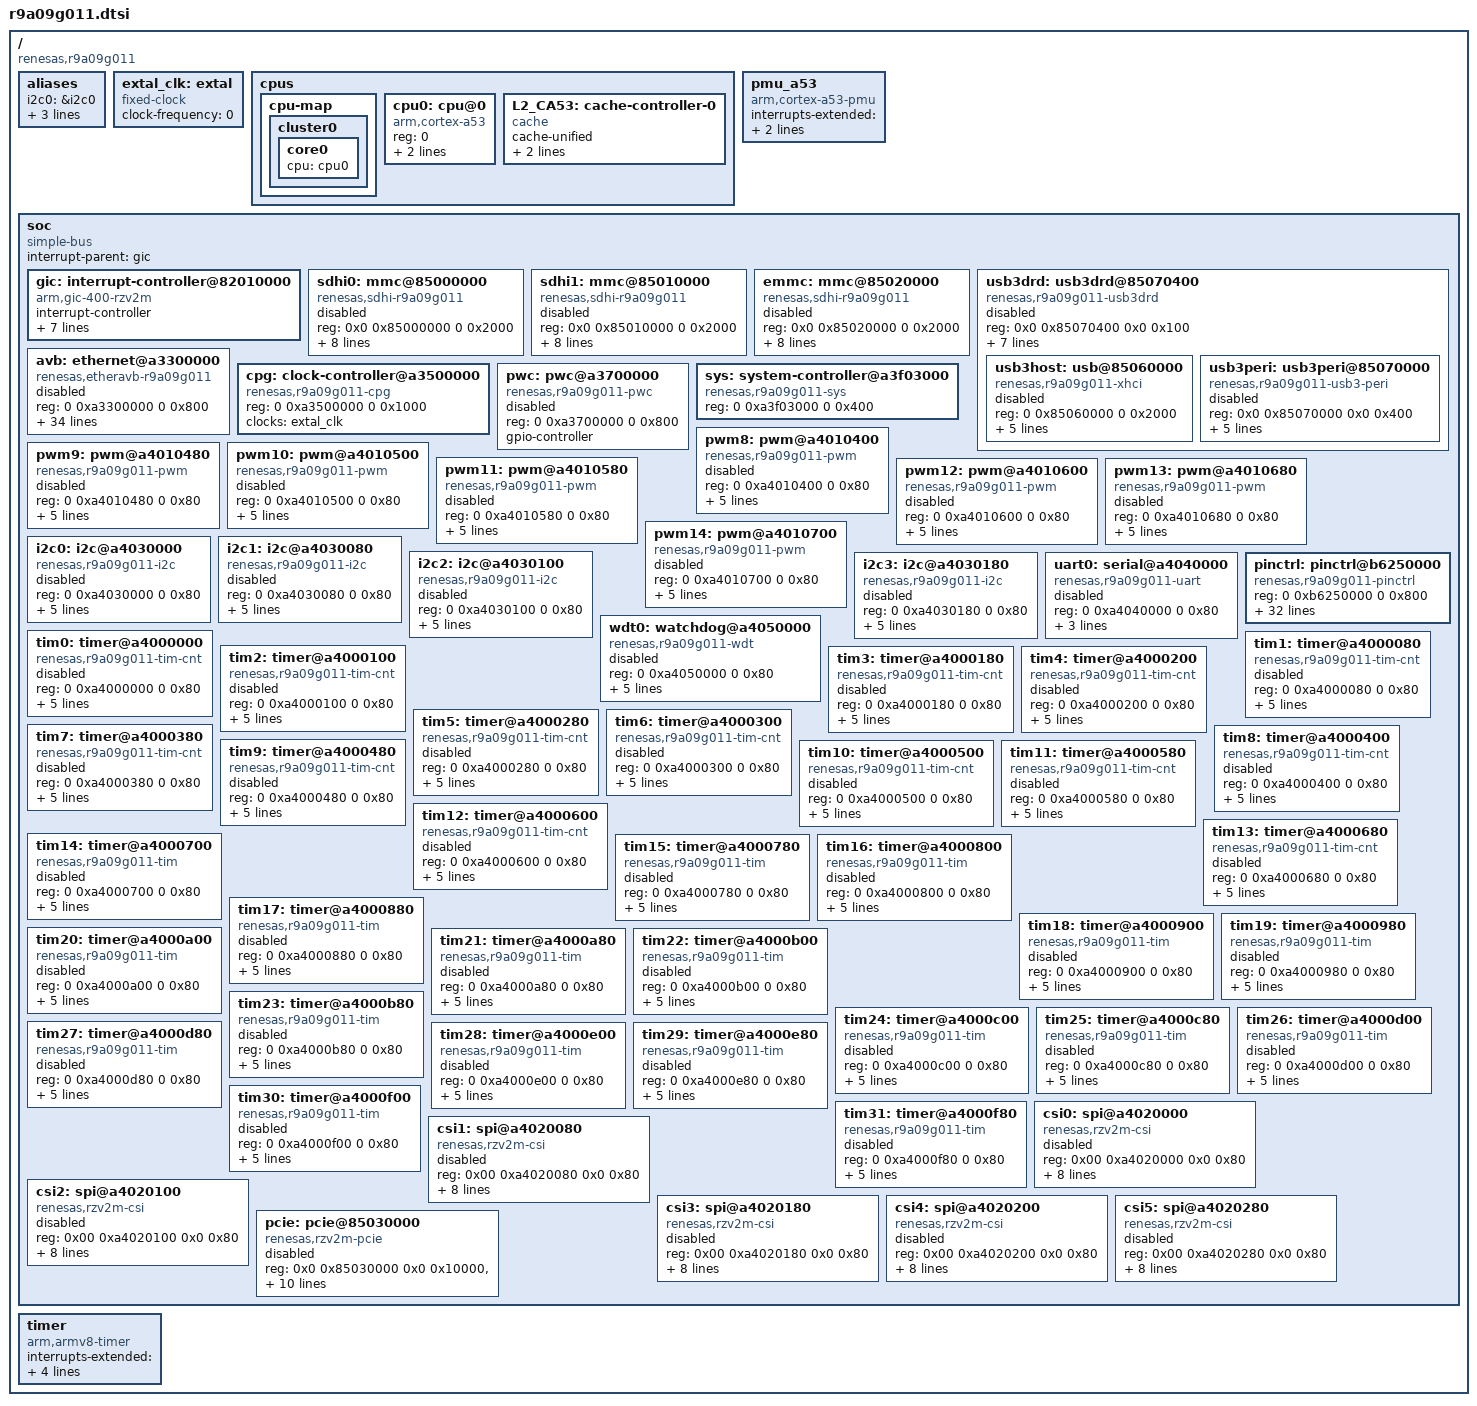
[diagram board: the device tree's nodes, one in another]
// SPDX-License-Identifier: (GPL-2.0-only OR BSD-2-Clause)
/*
 * Device Tree Source for the RZ/V2M SoC
 *
 * Copyright (C) 2022 Renesas Electronics Corp.
 */

#include <dt-bindings/interrupt-controller/arm-gic.h>
#include <dt-bindings/clock/r9a09g011-cpg.h>

/ {
	compatible = "renesas,r9a09g011";
	#address-cells = <2>;
	#size-cells = <2>;

	aliases {
		i2c0 = &i2c0;
		i2c1 = &i2c1;
		i2c2 = &i2c2;
		i2c3 = &i2c3;
	};

	/* clock can be either from exclk or crystal oscillator (XIN/XOUT) */
	extal_clk: extal {
		compatible = "fixed-clock";
		#clock-cells = <0>;
		/* This value must be overridden by the board */
		clock-frequency = <0>;
	};

	cpus {
		#address-cells = <1>;
		#size-cells = <0>;

		cpu-map {
			cluster0 {
				core0 {
					cpu = <&cpu0>;
				};
			};
		};

		cpu0: cpu@0 {
			compatible = "arm,cortex-a53";
			reg = <0>;
			device_type = "cpu";
			next-level-cache = <&L2_CA53>;
			clocks = <&cpg CPG_MOD R9A09G011_CA53_CLK>;
		};

		L2_CA53: cache-controller-0 {
			compatible = "cache";
			cache-unified;
			cache-level = <2>;
			cache-size = <0x80000>;
		};
	};


    	pmu_a53 { /* Support only for core0 not core1 */
		compatible = "arm,cortex-a53-pmu";
		interrupts-extended = <&gic GIC_SPI 6 IRQ_TYPE_LEVEL_HIGH>;
		interrupt-affinity = <&cpu0>;
    	};

	soc: soc {
		compatible = "simple-bus";
		interrupt-parent = <&gic>;
		#address-cells = <2>;
		#size-cells = <2>;
		ranges;

		gic: interrupt-controller@82010000 {
			compatible = "arm,gic-400-rzv2m";
			#interrupt-cells = <3>;
			#address-cells = <0>;
			interrupt-controller;
			reg = <0x0 0x82010000 0 0x1000>,
			      <0x0 0x82020000 0 0x20000>,
			      <0x0 0x82040000 0 0x20000>,
			      <0x0 0x82060000 0 0x20000>;
			interrupts = <GIC_PPI 9 (GIC_CPU_MASK_SIMPLE(1) | IRQ_TYPE_LEVEL_HIGH)>;
			clocks = <&cpg CPG_MOD R9A09G011_GIC_CLK>;
			clock-names = "clk";
		};

		sdhi0: mmc@85000000 {
			compatible = "renesas,sdhi-r9a09g011",
				     "renesas,rcar-gen3-sdhi";
			reg = <0x0 0x85000000 0 0x2000>;
			interrupts = <GIC_SPI 356 IRQ_TYPE_LEVEL_HIGH>,
				     <GIC_SPI 357 IRQ_TYPE_LEVEL_HIGH>;
			clocks = <&cpg CPG_MOD R9A09G011_SDI0_IMCLK>,
				 <&cpg CPG_MOD R9A09G011_SDI0_CLK_HS>,
				 <&cpg CPG_MOD R9A09G011_SDI0_IMCLK2>,
				 <&cpg CPG_MOD R9A09G011_SDI0_ACLK>;
			clock-names = "core", "clkh", "cd", "aclk";
			resets = <&cpg R9A09G011_SDI0_IXRST>;
			power-domains = <&cpg>;
			status = "disabled";
		};

		sdhi1: mmc@85010000  {
			compatible = "renesas,sdhi-r9a09g011",
				     "renesas,rcar-gen3-sdhi";
			reg = <0x0 0x85010000 0 0x2000>;
			interrupts = <GIC_SPI 358 IRQ_TYPE_LEVEL_HIGH>,
				     <GIC_SPI 359 IRQ_TYPE_LEVEL_HIGH>;
			clocks = <&cpg CPG_MOD R9A09G011_SDI1_IMCLK>,
				 <&cpg CPG_MOD R9A09G011_SDI1_CLK_HS>,
				 <&cpg CPG_MOD R9A09G011_SDI1_IMCLK2>,
				 <&cpg CPG_MOD R9A09G011_SDI1_ACLK>;
			clock-names = "core", "clkh", "cd", "aclk";
			resets = <&cpg R9A09G011_SDI1_IXRST>;
			power-domains = <&cpg>;
			status = "disabled";
		};

		emmc: mmc@85020000  {
			compatible = "renesas,sdhi-r9a09g011",
				     "renesas,rcar-gen3-sdhi";
			reg = <0x0 0x85020000 0 0x2000>;
			interrupts = <GIC_SPI 354 IRQ_TYPE_LEVEL_HIGH>,
				     <GIC_SPI 355 IRQ_TYPE_LEVEL_HIGH>;
			clocks = <&cpg CPG_MOD R9A09G011_EMM_IMCLK>,
				 <&cpg CPG_MOD R9A09G011_EMM_CLK_HS>,
				 <&cpg CPG_MOD R9A09G011_EMM_IMCLK2>,
				 <&cpg CPG_MOD R9A09G011_EMM_ACLK>;
			clock-names = "core", "clkh", "cd", "aclk";
			resets = <&cpg R9A09G011_EMM_IXRST>;
			power-domains = <&cpg>;
			status = "disabled";
		};

		usb3drd: usb3drd@85070400 {
			compatible = "renesas,r9a09g011-usb3drd",
				     "renesas,rzv2m-usb3drd";
			reg = <0x0 0x85070400 0x0 0x100>;
			interrupts = <GIC_SPI 242 IRQ_TYPE_LEVEL_HIGH>,
				      <GIC_SPI 243 IRQ_TYPE_LEVEL_HIGH>,
				      <GIC_SPI 244 IRQ_TYPE_LEVEL_HIGH>;
			interrupt-names = "drd", "bc", "gpi";
			clocks = <&cpg CPG_MOD R9A09G011_USB_ACLK_P>,
				 <&cpg CPG_MOD R9A09G011_USB_PCLK>;
			clock-names = "axi", "reg";
			resets = <&cpg R9A09G011_USB_DRD_RESET>;
			power-domains = <&cpg>;
			ranges;
			#address-cells = <2>;
			#size-cells = <2>;
			status = "disabled";

			usb3host: usb@85060000 {
				compatible = "renesas,r9a09g011-xhci",
					     "renesas,rzv2m-xhci";
				reg = <0 0x85060000 0 0x2000>;
				interrupts = <GIC_SPI 245 IRQ_TYPE_LEVEL_HIGH>;
				clocks = <&cpg CPG_MOD R9A09G011_USB_ACLK_H>,
					 <&cpg CPG_MOD R9A09G011_USB_PCLK>;
				clock-names = "axi", "reg";
				resets = <&cpg R9A09G011_USB_ARESETN_H>;
				power-domains = <&cpg>;
				status = "disabled";
			};

			usb3peri: usb3peri@85070000 {
				compatible = "renesas,r9a09g011-usb3-peri",
					     "renesas,rzv2m-usb3-peri";
				reg = <0x0 0x85070000 0x0 0x400>;
				interrupts = <GIC_SPI 246 IRQ_TYPE_LEVEL_HIGH>;
				clocks = <&cpg CPG_MOD R9A09G011_USB_ACLK_P>,
					 <&cpg CPG_MOD R9A09G011_USB_PCLK>;
				clock-names = "axi", "reg";
				resets = <&cpg R9A09G011_USB_ARESETN_P>;
				power-domains = <&cpg>;
				status = "disabled";
			};
		};

		avb: ethernet@a3300000 {
			compatible = "renesas,etheravb-r9a09g011","renesas,etheravb-rzv2m";
			reg = <0 0xa3300000 0 0x800>;
			interrupts = <GIC_SPI 251 IRQ_TYPE_LEVEL_HIGH>, /* ch0: Rx0 BE */
				     <GIC_SPI 252 IRQ_TYPE_LEVEL_HIGH>, /* ch1: Rx1 NC */
				     <GIC_SPI 253 IRQ_TYPE_LEVEL_HIGH>,
				     <GIC_SPI 254 IRQ_TYPE_LEVEL_HIGH>,
				     <GIC_SPI 255 IRQ_TYPE_LEVEL_HIGH>,
				     <GIC_SPI 256 IRQ_TYPE_LEVEL_HIGH>,
				     <GIC_SPI 257 IRQ_TYPE_LEVEL_HIGH>,
				     <GIC_SPI 258 IRQ_TYPE_LEVEL_HIGH>,
				     <GIC_SPI 259 IRQ_TYPE_LEVEL_HIGH>,
				     <GIC_SPI 260 IRQ_TYPE_LEVEL_HIGH>,
				     <GIC_SPI 261 IRQ_TYPE_LEVEL_HIGH>,
				     <GIC_SPI 262 IRQ_TYPE_LEVEL_HIGH>,
				     <GIC_SPI 263 IRQ_TYPE_LEVEL_HIGH>,
				     <GIC_SPI 264 IRQ_TYPE_LEVEL_HIGH>,
				     <GIC_SPI 265 IRQ_TYPE_LEVEL_HIGH>,
				     <GIC_SPI 266 IRQ_TYPE_LEVEL_HIGH>,
				     <GIC_SPI 267 IRQ_TYPE_LEVEL_HIGH>,
				     <GIC_SPI 268 IRQ_TYPE_LEVEL_HIGH>,
				     <GIC_SPI 269 IRQ_TYPE_LEVEL_HIGH>, /* ch18: Tx0 BE */
				     <GIC_SPI 270 IRQ_TYPE_LEVEL_HIGH>, /* ch19: Tx1 NC */
				     <GIC_SPI 271 IRQ_TYPE_LEVEL_HIGH>,
				     <GIC_SPI 272 IRQ_TYPE_LEVEL_HIGH>,
				     <GIC_SPI 273 IRQ_TYPE_LEVEL_HIGH>, /* DiA */
				     <GIC_SPI 274 IRQ_TYPE_LEVEL_HIGH>, /* DiB */
				     <GIC_SPI 275 IRQ_TYPE_LEVEL_HIGH>, /* Line1_A */
				     <GIC_SPI 276 IRQ_TYPE_LEVEL_HIGH>, /* Line1_B */
				     <GIC_SPI 277 IRQ_TYPE_LEVEL_HIGH>, /* Line2_A */
				     <GIC_SPI 278 IRQ_TYPE_LEVEL_HIGH>, /* Line2_B */
				     <GIC_SPI 279 IRQ_TYPE_LEVEL_HIGH>; /* Line3 MAC */
			interrupt-names = "ch0", "ch1", "ch2", "ch3",
					  "ch4", "ch5", "ch6", "ch7",
					  "ch8", "ch9", "ch10", "ch11",
					  "ch12", "ch13", "ch14", "ch15",
					  "ch16", "ch17", "ch18", "ch19",
					  "ch20", "ch21", "dia", "dib",
					  "err_a", "err_b", "mgmt_a", "mgmt_b",
					  "line3";
			clocks = <&cpg CPG_MOD R9A09G011_ETH0_CLK_AXI>,
				 <&cpg CPG_MOD R9A09G011_ETH0_CLK_CHI>,
				 <&cpg CPG_MOD R9A09G011_ETH0_GPTP_EXT>;
			clock-names = "axi", "chi", "gptp";
			resets = <&cpg R9A09G011_ETH0_RST_HW_N>;
			power-domains = <&cpg>;
			#address-cells = <1>;
			#size-cells = <0>;
			status = "disabled";
		};

		cpg: clock-controller@a3500000 {
			compatible = "renesas,r9a09g011-cpg";
			reg = <0 0xa3500000 0 0x1000>;
			clocks = <&extal_clk>;
			clock-names = "extal";
			#clock-cells = <2>;
			#reset-cells = <1>;
			#power-domain-cells = <0>;
		};

		pwc: pwc@a3700000 {
			compatible = "renesas,r9a09g011-pwc", "renesas,rzv2m-pwc";
			reg = <0 0xa3700000 0 0x800>;
			gpio-controller;
			#gpio-cells = <2>;
			status = "disabled";
		};

		sys: system-controller@a3f03000 {
			compatible = "renesas,r9a09g011-sys";
			reg = <0 0xa3f03000 0 0x400>;
		};

		pwm8: pwm@a4010400 {
			compatible = "renesas,r9a09g011-pwm",
				     "renesas,rzv2m-pwm";
			reg = <0 0xa4010400 0 0x80>;
			interrupts = <GIC_SPI 376 IRQ_TYPE_LEVEL_HIGH>;
			clocks = <&cpg CPG_MOD R9A09G011_CPERI_GRPF_PCLK>,
				 <&cpg CPG_MOD R9A09G011_PWM8_CLK>;
			clock-names = "apb", "pwm";
			resets = <&cpg R9A09G011_PWM_GPF_PRESETN>;
			power-domains = <&cpg>;
			#pwm-cells = <2>;
			status = "disabled";
		};

		pwm9: pwm@a4010480 {
			compatible = "renesas,r9a09g011-pwm",
				     "renesas,rzv2m-pwm";
			reg = <0 0xa4010480 0 0x80>;
			interrupts = <GIC_SPI 377 IRQ_TYPE_LEVEL_HIGH>;
			clocks = <&cpg CPG_MOD R9A09G011_CPERI_GRPF_PCLK>,
				 <&cpg CPG_MOD R9A09G011_PWM9_CLK>;
			clock-names = "apb", "pwm";
			resets = <&cpg R9A09G011_PWM_GPF_PRESETN>;
			power-domains = <&cpg>;
			#pwm-cells = <2>;
			status = "disabled";
		};

		pwm10: pwm@a4010500 {
			compatible = "renesas,r9a09g011-pwm",
				     "renesas,rzv2m-pwm";
			reg = <0 0xa4010500 0 0x80>;
			interrupts = <GIC_SPI 378 IRQ_TYPE_LEVEL_HIGH>;
			clocks = <&cpg CPG_MOD R9A09G011_CPERI_GRPF_PCLK>,
				 <&cpg CPG_MOD R9A09G011_PWM10_CLK>;
			clock-names = "apb", "pwm";
			resets = <&cpg R9A09G011_PWM_GPF_PRESETN>;
			power-domains = <&cpg>;
			#pwm-cells = <2>;
			status = "disabled";
		};

		pwm11: pwm@a4010580 {
			compatible = "renesas,r9a09g011-pwm",
				     "renesas,rzv2m-pwm";
			reg = <0 0xa4010580 0 0x80>;
			interrupts = <GIC_SPI 379 IRQ_TYPE_LEVEL_HIGH>;
			clocks = <&cpg CPG_MOD R9A09G011_CPERI_GRPF_PCLK>,
				 <&cpg CPG_MOD R9A09G011_PWM11_CLK>;
			clock-names = "apb", "pwm";
			resets = <&cpg R9A09G011_PWM_GPF_PRESETN>;
			power-domains = <&cpg>;
			#pwm-cells = <2>;
			status = "disabled";
		};

		pwm12: pwm@a4010600 {
			compatible = "renesas,r9a09g011-pwm",
				     "renesas,rzv2m-pwm";
			reg = <0 0xa4010600 0 0x80>;
			interrupts = <GIC_SPI 380 IRQ_TYPE_LEVEL_HIGH>;
			clocks = <&cpg CPG_MOD R9A09G011_CPERI_GRPF_PCLK>,
				 <&cpg CPG_MOD R9A09G011_PWM12_CLK>;
			clock-names = "apb", "pwm";
			resets = <&cpg R9A09G011_PWM_GPF_PRESETN>;
			power-domains = <&cpg>;
			#pwm-cells = <2>;
			status = "disabled";
		};

		pwm13: pwm@a4010680 {
			compatible = "renesas,r9a09g011-pwm",
				     "renesas,rzv2m-pwm";
			reg = <0 0xa4010680 0 0x80>;
			interrupts = <GIC_SPI 381 IRQ_TYPE_LEVEL_HIGH>;
			clocks = <&cpg CPG_MOD R9A09G011_CPERI_GRPF_PCLK>,
				 <&cpg CPG_MOD R9A09G011_PWM13_CLK>;
			clock-names = "apb", "pwm";
			resets = <&cpg R9A09G011_PWM_GPF_PRESETN>;
			power-domains = <&cpg>;
			#pwm-cells = <2>;
			status = "disabled";
		};

		pwm14: pwm@a4010700 {
			compatible = "renesas,r9a09g011-pwm",
				     "renesas,rzv2m-pwm";
			reg = <0 0xa4010700 0 0x80>;
			interrupts = <GIC_SPI 382 IRQ_TYPE_LEVEL_HIGH>;
			clocks = <&cpg CPG_MOD R9A09G011_CPERI_GRPF_PCLK>,
				 <&cpg CPG_MOD R9A09G011_PWM14_CLK>;
			clock-names = "apb", "pwm";
			resets = <&cpg R9A09G011_PWM_GPF_PRESETN>;
			power-domains = <&cpg>;
			#pwm-cells = <2>;
			status = "disabled";
		};

		i2c0: i2c@a4030000 {
			#address-cells = <1>;
			#size-cells = <0>;
			compatible = "renesas,r9a09g011-i2c", "renesas,rzv2m-i2c";
			reg = <0 0xa4030000 0 0x80>;
			interrupts = <GIC_SPI 232 IRQ_TYPE_EDGE_RISING>,
				     <GIC_SPI 236 IRQ_TYPE_EDGE_RISING>;
			interrupt-names = "tia", "tis";
			clocks = <&cpg CPG_MOD R9A09G011_IIC_PCLK0>;
			resets = <&cpg R9A09G011_IIC_GPA_PRESETN>;
			power-domains = <&cpg>;
			status = "disabled";
		};

                i2c1: i2c@a4030080 {
                        #address-cells = <1>;
                        #size-cells = <0>;
                        compatible = "renesas,r9a09g011-i2c", "renesas,rzv2m-i2c";
                        reg = <0 0xa4030080 0 0x80>;
                        interrupts = <GIC_SPI 233 IRQ_TYPE_EDGE_RISING>,
                                     <GIC_SPI 237 IRQ_TYPE_EDGE_RISING>;
                        interrupt-names = "tia", "tis";
                        clocks = <&cpg CPG_MOD R9A09G011_IIC_PCLK0>;
                        resets = <&cpg R9A09G011_IIC_GPA_PRESETN>;
                        power-domains = <&cpg>;
                        status = "disabled";
                };

		i2c2: i2c@a4030100 {
			#address-cells = <1>;
			#size-cells = <0>;
			compatible = "renesas,r9a09g011-i2c", "renesas,rzv2m-i2c";
			reg = <0 0xa4030100 0 0x80>;
			interrupts = <GIC_SPI 234 IRQ_TYPE_EDGE_RISING>,
				     <GIC_SPI 238 IRQ_TYPE_EDGE_RISING>;
			interrupt-names = "tia", "tis";
			clocks = <&cpg CPG_MOD R9A09G011_IIC_PCLK1>;
			resets = <&cpg R9A09G011_IIC_GPB_PRESETN>;
			power-domains = <&cpg>;
			status = "disabled";
		};

                i2c3: i2c@a4030180 {
                        #address-cells = <1>;
                        #size-cells = <0>;
                        compatible = "renesas,r9a09g011-i2c", "renesas,rzv2m-i2c";
                        reg = <0 0xa4030180 0 0x80>;
                        interrupts = <GIC_SPI 235 IRQ_TYPE_EDGE_RISING>,
                                     <GIC_SPI 239 IRQ_TYPE_EDGE_RISING>;
                        interrupt-names = "tia", "tis";
                        clocks = <&cpg CPG_MOD R9A09G011_IIC_PCLK1>;
                        resets = <&cpg R9A09G011_IIC_GPB_PRESETN>;
                        power-domains = <&cpg>;
                        status = "disabled";
                };

		uart0: serial@a4040000 {
			compatible = "renesas,r9a09g011-uart", "renesas,em-uart";
			reg = <0 0xa4040000 0 0x80>;
			interrupts = <GIC_SPI 240 IRQ_TYPE_LEVEL_HIGH>;
			clocks = <&cpg CPG_MOD R9A09G011_URT0_CLK>,
				 <&cpg CPG_MOD R9A09G011_URT_PCLK>;
			clock-names = "sclk", "pclk";
			status = "disabled";
		};

		wdt0: watchdog@a4050000 {
			compatible = "renesas,r9a09g011-wdt",
				     "renesas,rzv2m-wdt";
			reg = <0 0xa4050000 0 0x80>;
			clocks = <&cpg CPG_MOD R9A09G011_WDT0_PCLK>,
				 <&cpg CPG_MOD R9A09G011_WDT0_CLK>;
			clock-names = "pclk", "oscclk";
			interrupts = <GIC_SPI 43 IRQ_TYPE_LEVEL_HIGH>;
			resets = <&cpg R9A09G011_WDT0_PRESETN>;
			power-domains = <&cpg>;
			status = "disabled";
		};

		pinctrl: pinctrl@b6250000 {
			compatible = "renesas,r9a09g011-pinctrl";
			reg = <0 0xb6250000 0 0x800>;
			gpio-controller;
			#gpio-cells = <2>;
			gpio-ranges = <&pinctrl 0 0 352>;
			interrupt-controller;
			#interrupt-cells = <2>;
			interrupts = <GIC_SPI 72 IRQ_TYPE_LEVEL_HIGH>,
				     <GIC_SPI 73 IRQ_TYPE_LEVEL_HIGH>,
				     <GIC_SPI 74 IRQ_TYPE_LEVEL_HIGH>,
				     <GIC_SPI 75 IRQ_TYPE_LEVEL_HIGH>,
				     <GIC_SPI 84 IRQ_TYPE_LEVEL_HIGH>,
				     <GIC_SPI 85 IRQ_TYPE_LEVEL_HIGH>,
				     <GIC_SPI 86 IRQ_TYPE_LEVEL_HIGH>,
				     <GIC_SPI 87 IRQ_TYPE_LEVEL_HIGH>,
				     <GIC_SPI 88 IRQ_TYPE_LEVEL_HIGH>,
				     <GIC_SPI 89 IRQ_TYPE_LEVEL_HIGH>,
				     <GIC_SPI 90 IRQ_TYPE_LEVEL_HIGH>,
				     <GIC_SPI 92 IRQ_TYPE_LEVEL_HIGH>,
				     <GIC_SPI 93 IRQ_TYPE_LEVEL_HIGH>,
				     <GIC_SPI 94 IRQ_TYPE_LEVEL_HIGH>,
				     <GIC_SPI 95 IRQ_TYPE_LEVEL_HIGH>,
				     <GIC_SPI 96 IRQ_TYPE_LEVEL_HIGH>,
				     <GIC_SPI 97 IRQ_TYPE_LEVEL_HIGH>,
				     <GIC_SPI 98 IRQ_TYPE_LEVEL_HIGH>,
				     <GIC_SPI 99 IRQ_TYPE_LEVEL_HIGH>,
				     <GIC_SPI 100 IRQ_TYPE_LEVEL_HIGH>,
				     <GIC_SPI 101 IRQ_TYPE_LEVEL_HIGH>,
				     <GIC_SPI 102 IRQ_TYPE_LEVEL_HIGH>,
				     <GIC_SPI 103 IRQ_TYPE_LEVEL_HIGH>,
				     <GIC_SPI 104 IRQ_TYPE_LEVEL_HIGH>,
				     <GIC_SPI 105 IRQ_TYPE_LEVEL_HIGH>,
				     <GIC_SPI 106 IRQ_TYPE_LEVEL_HIGH>;
			interrupt-names = "inexint4", "inexint5",
					  "inexint6", "inexint7",
					  "inexint16", "inexint17",
					  "inexint18", "inexint19",
					  "inexint20", "inexint21",
					  "inexint22", "inexint24",
					  "inexint25", "inexint26",
					  "inexint27", "inexint28",
					  "inexint29", "inexint30",
					  "inexint31", "inexint32",
					  "inexint33", "inexint34",
					  "inexint35", "inexint36",
					  "inexint37", "inexint38";
			clocks = <&cpg CPG_MOD R9A09G011_PFC_PCLK>;
			power-domains = <&cpg>;
			resets = <&cpg R9A09G011_PFC_PRESETN>;
		};

		tim0: timer@a4000000 {
			compatible = "renesas,r9a09g011-tim-cnt",
				     "renesas,rzv2m-tim-cnt";
			reg = <0 0xa4000000 0 0x80>;
			interrupts = <GIC_SPI 107 IRQ_TYPE_LEVEL_HIGH>;
			clocks = <&cpg CPG_MOD R9A09G011_CPERI_GRPA_PCLK>,
				 <&cpg CPG_MOD R9A09G011_TIM0_CLK>;
			clock-names = "apb", "timclk";
			resets = <&cpg R9A09G011_TIM_GPA_PRESETN>;
			power-domains = <&cpg>;
			status = "disabled";
		};

		tim1: timer@a4000080 {
			compatible = "renesas,r9a09g011-tim-cnt",
				     "renesas,rzv2m-tim-cnt";
			reg = <0 0xa4000080 0 0x80>;
			interrupts = <GIC_SPI 108 IRQ_TYPE_LEVEL_HIGH>;
			clocks = <&cpg CPG_MOD R9A09G011_CPERI_GRPA_PCLK>,
				 <&cpg CPG_MOD R9A09G011_TIM1_CLK>;
			clock-names = "apb", "timclk";
			resets = <&cpg R9A09G011_TIM_GPA_PRESETN>;
			power-domains = <&cpg>;
			status = "disabled";
		};

		tim2: timer@a4000100 {
			compatible = "renesas,r9a09g011-tim-cnt",
				     "renesas,rzv2m-tim-cnt";
			reg = <0 0xa4000100 0 0x80>;
			interrupts = <GIC_SPI 109 IRQ_TYPE_LEVEL_HIGH>;
			clocks = <&cpg CPG_MOD R9A09G011_CPERI_GRPA_PCLK>,
				 <&cpg CPG_MOD R9A09G011_TIM2_CLK>;
			clock-names = "apb", "timclk";
			resets = <&cpg R9A09G011_TIM_GPA_PRESETN>;
			power-domains = <&cpg>;
			status = "disabled";
		};

		tim3: timer@a4000180 {
			compatible = "renesas,r9a09g011-tim-cnt",
				     "renesas,rzv2m-tim-cnt";
			reg = <0 0xa4000180 0 0x80>;
			interrupts = <GIC_SPI 110 IRQ_TYPE_LEVEL_HIGH>;
			clocks = <&cpg CPG_MOD R9A09G011_CPERI_GRPA_PCLK>,
				 <&cpg CPG_MOD R9A09G011_TIM3_CLK>;
			clock-names = "apb", "timclk";
			resets = <&cpg R9A09G011_TIM_GPA_PRESETN>;
			power-domains = <&cpg>;
			status = "disabled";
		};

		tim4: timer@a4000200 {
			compatible = "renesas,r9a09g011-tim-cnt",
				     "renesas,rzv2m-tim-cnt";
			reg = <0 0xa4000200 0 0x80>;
			interrupts = <GIC_SPI 111 IRQ_TYPE_LEVEL_HIGH>;
			clocks = <&cpg CPG_MOD R9A09G011_CPERI_GRPA_PCLK>,
				 <&cpg CPG_MOD R9A09G011_TIM4_CLK>;
			clock-names = "apb", "timclk";
			resets = <&cpg R9A09G011_TIM_GPA_PRESETN>;
			power-domains = <&cpg>;
			status = "disabled";
		};

		tim5: timer@a4000280 {
			compatible = "renesas,r9a09g011-tim-cnt",
				     "renesas,rzv2m-tim-cnt";
			reg = <0 0xa4000280 0 0x80>;
			interrupts = <GIC_SPI 112 IRQ_TYPE_LEVEL_HIGH>;
			clocks = <&cpg CPG_MOD R9A09G011_CPERI_GRPA_PCLK>,
				 <&cpg CPG_MOD R9A09G011_TIM5_CLK>;
			clock-names = "apb", "timclk";
			resets = <&cpg R9A09G011_TIM_GPA_PRESETN>;
			power-domains = <&cpg>;
			status = "disabled";
		};

		tim6: timer@a4000300 {
			compatible = "renesas,r9a09g011-tim-cnt",
				     "renesas,rzv2m-tim-cnt";
			reg = <0 0xa4000300 0 0x80>;
			interrupts = <GIC_SPI 113 IRQ_TYPE_LEVEL_HIGH>;
			clocks = <&cpg CPG_MOD R9A09G011_CPERI_GRPA_PCLK>,
				 <&cpg CPG_MOD R9A09G011_TIM6_CLK>;
			clock-names = "apb", "timclk";
			resets = <&cpg R9A09G011_TIM_GPA_PRESETN>;
			power-domains = <&cpg>;
			status = "disabled";
		};

		tim7: timer@a4000380 {
			compatible = "renesas,r9a09g011-tim-cnt",
				     "renesas,rzv2m-tim-cnt";
			reg = <0 0xa4000380 0 0x80>;
			interrupts = <GIC_SPI 114 IRQ_TYPE_LEVEL_HIGH>;
			clocks = <&cpg CPG_MOD R9A09G011_CPERI_GRPA_PCLK>,
				 <&cpg CPG_MOD R9A09G011_TIM15_CLK>;
			clock-names = "apb", "timclk";
			resets = <&cpg R9A09G011_TIM_GPA_PRESETN>;
			power-domains = <&cpg>;
			status = "disabled";
		};

		tim8: timer@a4000400 {
			compatible = "renesas,r9a09g011-tim-cnt",
				     "renesas,rzv2m-tim-cnt";
			reg = <0 0xa4000400 0 0x80>;
			interrupts = <GIC_SPI 115 IRQ_TYPE_LEVEL_HIGH>;
			clocks = <&cpg CPG_MOD R9A09G011_CPERI_GRPB_PCLK>,
				 <&cpg CPG_MOD R9A09G011_TIM8_CLK>;
			clock-names = "apb", "timclk";
			resets = <&cpg R9A09G011_TIM_GPB_PRESETN>;
			power-domains = <&cpg>;
			status = "disabled";
		};

		tim9: timer@a4000480 {
			compatible = "renesas,r9a09g011-tim-cnt",
				     "renesas,rzv2m-tim-cnt";
			reg = <0 0xa4000480 0 0x80>;
			interrupts = <GIC_SPI 116 IRQ_TYPE_LEVEL_HIGH>;
			clocks = <&cpg CPG_MOD R9A09G011_CPERI_GRPB_PCLK>,
				 <&cpg CPG_MOD R9A09G011_TIM9_CLK>;
			clock-names = "apb", "timclk";
			resets = <&cpg R9A09G011_TIM_GPB_PRESETN>;
			power-domains = <&cpg>;
			status = "disabled";
		};

		tim10: timer@a4000500 {
			compatible = "renesas,r9a09g011-tim-cnt",
				     "renesas,rzv2m-tim-cnt";
			reg = <0 0xa4000500 0 0x80>;
			interrupts = <GIC_SPI 117 IRQ_TYPE_LEVEL_HIGH>;
			clocks = <&cpg CPG_MOD R9A09G011_CPERI_GRPB_PCLK>,
				 <&cpg CPG_MOD R9A09G011_TIM10_CLK>;
			clock-names = "apb", "timclk";
			resets = <&cpg R9A09G011_TIM_GPB_PRESETN>;
			power-domains = <&cpg>;
			status = "disabled";
		};

		tim11: timer@a4000580 {
			compatible = "renesas,r9a09g011-tim-cnt",
				     "renesas,rzv2m-tim-cnt";
			reg = <0 0xa4000580 0 0x80>;
			interrupts = <GIC_SPI 118 IRQ_TYPE_LEVEL_HIGH>;
			clocks = <&cpg CPG_MOD R9A09G011_CPERI_GRPB_PCLK>,
				 <&cpg CPG_MOD R9A09G011_TIM11_CLK>;
			clock-names = "apb", "timclk";
			resets = <&cpg R9A09G011_TIM_GPB_PRESETN>;
			power-domains = <&cpg>;
			status = "disabled";
		};

		tim12: timer@a4000600 {
			compatible = "renesas,r9a09g011-tim-cnt",
				     "renesas,rzv2m-tim-cnt";
			reg = <0 0xa4000600 0 0x80>;
			interrupts = <GIC_SPI 119 IRQ_TYPE_LEVEL_HIGH>;
			clocks = <&cpg CPG_MOD R9A09G011_CPERI_GRPB_PCLK>,
				 <&cpg CPG_MOD R9A09G011_TIM12_CLK>;
			clock-names = "apb", "timclk";
			resets = <&cpg R9A09G011_TIM_GPB_PRESETN>;
			power-domains = <&cpg>;
			status = "disabled";
		};

		tim13: timer@a4000680 {
			compatible = "renesas,r9a09g011-tim-cnt",
				     "renesas,rzv2m-tim-cnt";
			reg = <0 0xa4000680 0 0x80>;
			interrupts = <GIC_SPI 120 IRQ_TYPE_LEVEL_HIGH>;
			clocks = <&cpg CPG_MOD R9A09G011_CPERI_GRPB_PCLK>,
				 <&cpg CPG_MOD R9A09G011_TIM13_CLK>;
			clock-names = "apb", "timclk";
			resets = <&cpg R9A09G011_TIM_GPB_PRESETN>;
			power-domains = <&cpg>;
			status = "disabled";
		};

		tim14: timer@a4000700 {
			compatible = "renesas,r9a09g011-tim",
				     "renesas,rzv2m-tim-cnt";
			reg = <0 0xa4000700 0 0x80>;
			interrupts = <GIC_SPI 121 IRQ_TYPE_LEVEL_HIGH>;
			clocks = <&cpg CPG_MOD R9A09G011_CPERI_GRPB_PCLK>,
				 <&cpg CPG_MOD R9A09G011_TIM14_CLK>;
			clock-names = "apb", "timclk";
			resets = <&cpg R9A09G011_TIM_GPB_PRESETN>;
			power-domains = <&cpg>;
			status = "disabled";
		};

		tim15: timer@a4000780 {
			compatible = "renesas,r9a09g011-tim",
				     "renesas,rzv2m-tim-cnt";
			reg = <0 0xa4000780 0 0x80>;
			interrupts = <GIC_SPI 122 IRQ_TYPE_LEVEL_HIGH>;
			clocks = <&cpg CPG_MOD R9A09G011_CPERI_GRPB_PCLK>,
				 <&cpg CPG_MOD R9A09G011_TIM15_CLK>;
			clock-names = "apb", "timclk";
			resets = <&cpg R9A09G011_TIM_GPB_PRESETN>;
			power-domains = <&cpg>;
			status = "disabled";
		};

		tim16: timer@a4000800 {
			compatible = "renesas,r9a09g011-tim",
				     "renesas,rzv2m-tim-cnt";
			reg = <0 0xa4000800 0 0x80>;
			interrupts = <GIC_SPI 123 IRQ_TYPE_LEVEL_HIGH>;
			clocks = <&cpg CPG_MOD R9A09G011_CPERI_GRPC_PCLK>,
				 <&cpg CPG_MOD R9A09G011_TIM16_CLK>;
			clock-names = "apb", "timclk";
			resets = <&cpg R9A09G011_TIM_GPC_PRESETN>;
			power-domains = <&cpg>;
			status = "disabled";
		};

		tim17: timer@a4000880 {
			compatible = "renesas,r9a09g011-tim",
				     "renesas,rzv2m-tim-cnt";
			reg = <0 0xa4000880 0 0x80>;
			interrupts = <GIC_SPI 124 IRQ_TYPE_LEVEL_HIGH>;
			clocks = <&cpg CPG_MOD R9A09G011_CPERI_GRPC_PCLK>,
				 <&cpg CPG_MOD R9A09G011_TIM17_CLK>;
			clock-names = "apb", "timclk";
			resets = <&cpg R9A09G011_TIM_GPC_PRESETN>;
			power-domains = <&cpg>;
			status = "disabled";
		};

		tim18: timer@a4000900 {
			compatible = "renesas,r9a09g011-tim",
				     "renesas,rzv2m-tim-cnt";
			reg = <0 0xa4000900 0 0x80>;
			interrupts = <GIC_SPI 125 IRQ_TYPE_LEVEL_HIGH>;
			clocks = <&cpg CPG_MOD R9A09G011_CPERI_GRPC_PCLK>,
				 <&cpg CPG_MOD R9A09G011_TIM18_CLK>;
			clock-names = "apb", "timclk";
			resets = <&cpg R9A09G011_TIM_GPC_PRESETN>;
			power-domains = <&cpg>;
			status = "disabled";
		};

		tim19: timer@a4000980 {
			compatible = "renesas,r9a09g011-tim",
				     "renesas,rzv2m-tim-cnt";
			reg = <0 0xa4000980 0 0x80>;
			interrupts = <GIC_SPI 126 IRQ_TYPE_LEVEL_HIGH>;
			clocks = <&cpg CPG_MOD R9A09G011_CPERI_GRPC_PCLK>,
				 <&cpg CPG_MOD R9A09G011_TIM19_CLK>;
			clock-names = "apb", "timclk";
			resets = <&cpg R9A09G011_TIM_GPC_PRESETN>;
			power-domains = <&cpg>;
			status = "disabled";
		};

		tim20: timer@a4000a00 {
			compatible = "renesas,r9a09g011-tim",
				     "renesas,rzv2m-tim-cnt";
			reg = <0 0xa4000a00 0 0x80>;
			interrupts = <GIC_SPI 127 IRQ_TYPE_LEVEL_HIGH>;
			clocks = <&cpg CPG_MOD R9A09G011_CPERI_GRPC_PCLK>,
				 <&cpg CPG_MOD R9A09G011_TIM20_CLK>;
			clock-names = "apb", "timclk";
			resets = <&cpg R9A09G011_TIM_GPC_PRESETN>;
			power-domains = <&cpg>;
			status = "disabled";
		};

		tim21: timer@a4000a80 {
			compatible = "renesas,r9a09g011-tim",
				     "renesas,rzv2m-tim-cnt";
			reg = <0 0xa4000a80 0 0x80>;
			interrupts = <GIC_SPI 128 IRQ_TYPE_LEVEL_HIGH>;
			clocks = <&cpg CPG_MOD R9A09G011_CPERI_GRPC_PCLK>,
				 <&cpg CPG_MOD R9A09G011_TIM21_CLK>;
			clock-names = "apb", "timclk";
			resets = <&cpg R9A09G011_TIM_GPC_PRESETN>;
			power-domains = <&cpg>;
			status = "disabled";
		};

		tim22: timer@a4000b00 {
			compatible = "renesas,r9a09g011-tim",
				     "renesas,rzv2m-tim-cnt";
			reg = <0 0xa4000b00 0 0x80>;
			interrupts = <GIC_SPI 129 IRQ_TYPE_LEVEL_HIGH>;
			clocks = <&cpg CPG_MOD R9A09G011_CPERI_GRPC_PCLK>,
				 <&cpg CPG_MOD R9A09G011_TIM22_CLK>;
			clock-names = "apb", "timclk";
			resets = <&cpg R9A09G011_TIM_GPC_PRESETN>;
			power-domains = <&cpg>;
			status = "disabled";
		};

		tim23: timer@a4000b80 {
			compatible = "renesas,r9a09g011-tim",
				     "renesas,rzv2m-tim-cnt";
			reg = <0 0xa4000b80 0 0x80>;
			interrupts = <GIC_SPI 130 IRQ_TYPE_LEVEL_HIGH>;
			clocks = <&cpg CPG_MOD R9A09G011_CPERI_GRPC_PCLK>,
				 <&cpg CPG_MOD R9A09G011_TIM23_CLK>;
			clock-names = "apb", "timclk";
			resets = <&cpg R9A09G011_TIM_GPC_PRESETN>;
			power-domains = <&cpg>;
			status = "disabled";

		};

		tim24: timer@a4000c00 {
			compatible = "renesas,r9a09g011-tim",
				     "renesas,rzv2m-tim-cnt";
			reg = <0 0xa4000c00 0 0x80>;
			interrupts = <GIC_SPI 131 IRQ_TYPE_LEVEL_HIGH>;
			clocks = <&cpg CPG_MOD R9A09G011_CPERI_GRPD_PCLK>,
				 <&cpg CPG_MOD R9A09G011_TIM24_CLK>;
			clock-names = "apb", "timclk";
			resets = <&cpg R9A09G011_TIM_GPD_PRESETN>;
			power-domains = <&cpg>;
			status = "disabled";
		};

		tim25: timer@a4000c80 {
			compatible = "renesas,r9a09g011-tim",
				     "renesas,rzv2m-tim-cnt";
			reg = <0 0xa4000c80 0 0x80>;
			interrupts = <GIC_SPI 132 IRQ_TYPE_LEVEL_HIGH>;
			clocks = <&cpg CPG_MOD R9A09G011_CPERI_GRPD_PCLK>,
				 <&cpg CPG_MOD R9A09G011_TIM25_CLK>;
			clock-names = "apb", "timclk";
			resets = <&cpg R9A09G011_TIM_GPD_PRESETN>;
			power-domains = <&cpg>;
			status = "disabled";
		};

		tim26: timer@a4000d00 {
			compatible = "renesas,r9a09g011-tim",
				     "renesas,rzv2m-tim-cnt";
			reg = <0 0xa4000d00 0 0x80>;
			interrupts = <GIC_SPI 133 IRQ_TYPE_LEVEL_HIGH>;
			clocks = <&cpg CPG_MOD R9A09G011_CPERI_GRPD_PCLK>,
				 <&cpg CPG_MOD R9A09G011_TIM26_CLK>;
			clock-names = "apb", "timclk";
			resets = <&cpg R9A09G011_TIM_GPD_PRESETN>;
			power-domains = <&cpg>;
			status = "disabled";
		};

		tim27: timer@a4000d80 {
			compatible = "renesas,r9a09g011-tim",
				     "renesas,rzv2m-tim-cnt";
			reg = <0 0xa4000d80 0 0x80>;
			interrupts = <GIC_SPI 134 IRQ_TYPE_LEVEL_HIGH>;
			clocks = <&cpg CPG_MOD R9A09G011_CPERI_GRPD_PCLK>,
				 <&cpg CPG_MOD R9A09G011_TIM27_CLK>;
			clock-names = "apb", "timclk";
			resets = <&cpg R9A09G011_TIM_GPD_PRESETN>;
			power-domains = <&cpg>;
			status = "disabled";
		};

		tim28: timer@a4000e00 {
			compatible = "renesas,r9a09g011-tim",
				     "renesas,rzv2m-tim-cnt";
			reg = <0 0xa4000e00 0 0x80>;
			interrupts = <GIC_SPI 135 IRQ_TYPE_LEVEL_HIGH>;
			clocks = <&cpg CPG_MOD R9A09G011_CPERI_GRPD_PCLK>,
				 <&cpg CPG_MOD R9A09G011_TIM28_CLK>;
			clock-names = "apb", "timclk";
			resets = <&cpg R9A09G011_TIM_GPD_PRESETN>;
			power-domains = <&cpg>;
			status = "disabled";
		};

		tim29: timer@a4000e80 {
			compatible = "renesas,r9a09g011-tim",
				     "renesas,rzv2m-tim-cnt";
			reg = <0 0xa4000e80 0 0x80>;
			interrupts = <GIC_SPI 136 IRQ_TYPE_LEVEL_HIGH>;
			clocks = <&cpg CPG_MOD R9A09G011_CPERI_GRPD_PCLK>,
				 <&cpg CPG_MOD R9A09G011_TIM29_CLK>;
			clock-names = "apb", "timclk";
			resets = <&cpg R9A09G011_TIM_GPD_PRESETN>;
			power-domains = <&cpg>;
			status = "disabled";
		};

		tim30: timer@a4000f00 {
			compatible = "renesas,r9a09g011-tim",
				     "renesas,rzv2m-tim-cnt";
			reg = <0 0xa4000f00 0 0x80>;
			interrupts = <GIC_SPI 137 IRQ_TYPE_LEVEL_HIGH>;
			clocks = <&cpg CPG_MOD R9A09G011_CPERI_GRPD_PCLK>,
				 <&cpg CPG_MOD R9A09G011_TIM30_CLK>;
			clock-names = "apb", "timclk";
			resets = <&cpg R9A09G011_TIM_GPD_PRESETN>;
			power-domains = <&cpg>;
			status = "disabled";
		};

		tim31: timer@a4000f80 {
			compatible = "renesas,r9a09g011-tim",
				     "renesas,rzv2m-tim-cnt";
			reg = <0 0xa4000f80 0 0x80>;
			interrupts = <GIC_SPI 138 IRQ_TYPE_LEVEL_HIGH>;
			clocks = <&cpg CPG_MOD R9A09G011_CPERI_GRPD_PCLK>,
				 <&cpg CPG_MOD R9A09G011_TIM31_CLK>;
			clock-names = "apb", "timclk";
			resets = <&cpg R9A09G011_TIM_GPD_PRESETN>;
			power-domains = <&cpg>;
			status = "disabled";
		};

		csi0: spi@a4020000 {
			compatible = "renesas,rzv2m-csi";
			reg = <0x00 0xa4020000 0x0 0x80>;
			interrupts = <GIC_SPI 226 IRQ_TYPE_LEVEL_HIGH>;
			clocks = <&cpg CPG_MOD R9A09G011_CSI0_CLK>,
				 <&cpg CPG_MOD R9A09G011_CPERI_GRPG_PCLK>;
			clock-names = "csiclk", "pclk";
			resets = <&cpg R9A09G011_CSI_GPG_PRESETN>;
			power-domains = <&cpg>;
			#address-cells = <1>;
			#size-cells = <0>;
			status = "disabled";
			interval_time = <0x2>;
			tx_trigger_lvl = <0x4>;
			rx_trigger_lvl = <0x4>;
		};

		csi1: spi@a4020080 {
			compatible = "renesas,rzv2m-csi";
			reg = <0x00 0xa4020080 0x0 0x80>;
			interrupts = <GIC_SPI 227 IRQ_TYPE_LEVEL_HIGH>;
			clocks = <&cpg CPG_MOD R9A09G011_CSI1_CLK>,
				 <&cpg CPG_MOD R9A09G011_CPERI_GRPG_PCLK>;
			clock-names = "csiclk", "pclk";
			resets = <&cpg R9A09G011_CSI_GPG_PRESETN>;
			power-domains = <&cpg>;
			#address-cells = <1>;
			#size-cells = <0>;
			status = "disabled";
			interval_time = <0x2>;
			tx_trigger_lvl = <0x4>;
			rx_trigger_lvl = <0x4>;
		};

		csi2: spi@a4020100 {
			compatible = "renesas,rzv2m-csi";
			reg = <0x00 0xa4020100 0x0 0x80>;
			interrupts = <GIC_SPI 228 IRQ_TYPE_LEVEL_HIGH>;
			clocks = <&cpg CPG_MOD R9A09G011_CSI2_CLK>,
				 <&cpg CPG_MOD R9A09G011_CPERI_GRPG_PCLK>;
			clock-names = "csiclk", "pclk";
			resets = <&cpg R9A09G011_CSI_GPG_PRESETN>;
			power-domains = <&cpg>;
			#address-cells = <1>;
			#size-cells = <0>;
			status = "disabled";
			interval_time = <0x2>;
			tx_trigger_lvl = <0x4>;
			rx_trigger_lvl = <0x4>;
		};

		csi3: spi@a4020180 {
			compatible = "renesas,rzv2m-csi";
			reg = <0x00 0xa4020180 0x0 0x80>;
			interrupts = <GIC_SPI 229 IRQ_TYPE_LEVEL_HIGH>;
			clocks = <&cpg CPG_MOD R9A09G011_CSI3_CLK>,
				 <&cpg CPG_MOD R9A09G011_CPERI_GRPG_PCLK>;
			clock-names = "csiclk", "pclk";
			resets = <&cpg R9A09G011_CSI_GPG_PRESETN>;
			power-domains = <&cpg>;
			#address-cells = <1>;
			#size-cells = <0>;
			status = "disabled";
			interval_time = <0x2>;
			tx_trigger_lvl = <0x4>;
			rx_trigger_lvl = <0x4>;
		};

		csi4: spi@a4020200 {
			compatible = "renesas,rzv2m-csi";
			reg = <0x00 0xa4020200 0x0 0x80>;
			interrupts = <GIC_SPI 230 IRQ_TYPE_LEVEL_HIGH>;
			clocks = <&cpg CPG_MOD R9A09G011_CSI4_CLK>,
				 <&cpg CPG_MOD R9A09G011_CPERI_GRPH_PCLK>;
			clock-names = "csiclk", "pclk";
			resets = <&cpg R9A09G011_CSI_GPH_PRESETN>;
			power-domains = <&cpg>;
			#address-cells = <1>;
			#size-cells = <0>;
			status = "disabled";
			interval_time = <0x2>;
			tx_trigger_lvl = <0x4>;
			rx_trigger_lvl = <0x4>;
		};

		csi5: spi@a4020280 {
			compatible = "renesas,rzv2m-csi";
			reg = <0x00 0xa4020280 0x0 0x80>;
			interrupts = <GIC_SPI 231 IRQ_TYPE_LEVEL_HIGH>;
			clocks = <&cpg CPG_MOD R9A09G011_CSI5_CLK>,
				 <&cpg CPG_MOD R9A09G011_CPERI_GRPH_PCLK>;
			clock-names = "csiclk", "pclk";
			resets = <&cpg R9A09G011_CSI_GPH_PRESETN>;
			power-domains = <&cpg>;
			#address-cells = <1>;
			#size-cells = <0>;
			status = "disabled";
			interval_time = <0x2>;
			tx_trigger_lvl = <0x4>;
			rx_trigger_lvl = <0x4>;
		};
		pcie: pcie@85030000 {
			compatible = "renesas,rzv2m-pcie";
			device_type = "pci";
			reg = <0x0 0x85030000 0x0 0x10000>, // PCI
			      <0x0 0xA3F03000 0x0 0x400>,   // PCI SYS
			      <0x0 0xA3F70000 0x0 0x800>;   // PCI PHY
			#address-cells = <0x3>;
			#size-cells = <0x2>;
			bus-range = <0x0 0xff>;
			linux,pci-domain = <0x0>;
			interrupts = <GIC_SPI 324 IRQ_TYPE_LEVEL_HIGH>;
			ranges = <0x03000000 0x0 0xc0000000 0x0 0xc0000000 0x0 0x00200000
			          0x03000000 0x0 0xc0300000 0x0 0xc0300000 0x0 0x08000000>;
			dma-ranges = <0x03000000 0x1 0x80000000 0x1 0x80000000 0x0 0x80000000>;
			#interrupt-cells = <0x1>;
			interrupt-map-mask = <0 0 0 0>;
			interrupt-map = <0 0 0 0 &gic GIC_SPI 324 IRQ_TYPE_LEVEL_HIGH>;
			status = "disabled";
		};
	};

	timer {
		compatible = "arm,armv8-timer";
		interrupts-extended = <&gic GIC_PPI 13 (GIC_CPU_MASK_SIMPLE(1) | IRQ_TYPE_LEVEL_LOW)>,
				      <&gic GIC_PPI 14 (GIC_CPU_MASK_SIMPLE(1) | IRQ_TYPE_LEVEL_LOW)>,
				      <&gic GIC_PPI 11 (GIC_CPU_MASK_SIMPLE(1) | IRQ_TYPE_LEVEL_LOW)>,
				      <&gic GIC_PPI 10 (GIC_CPU_MASK_SIMPLE(1) | IRQ_TYPE_LEVEL_LOW)>;
	};
};
